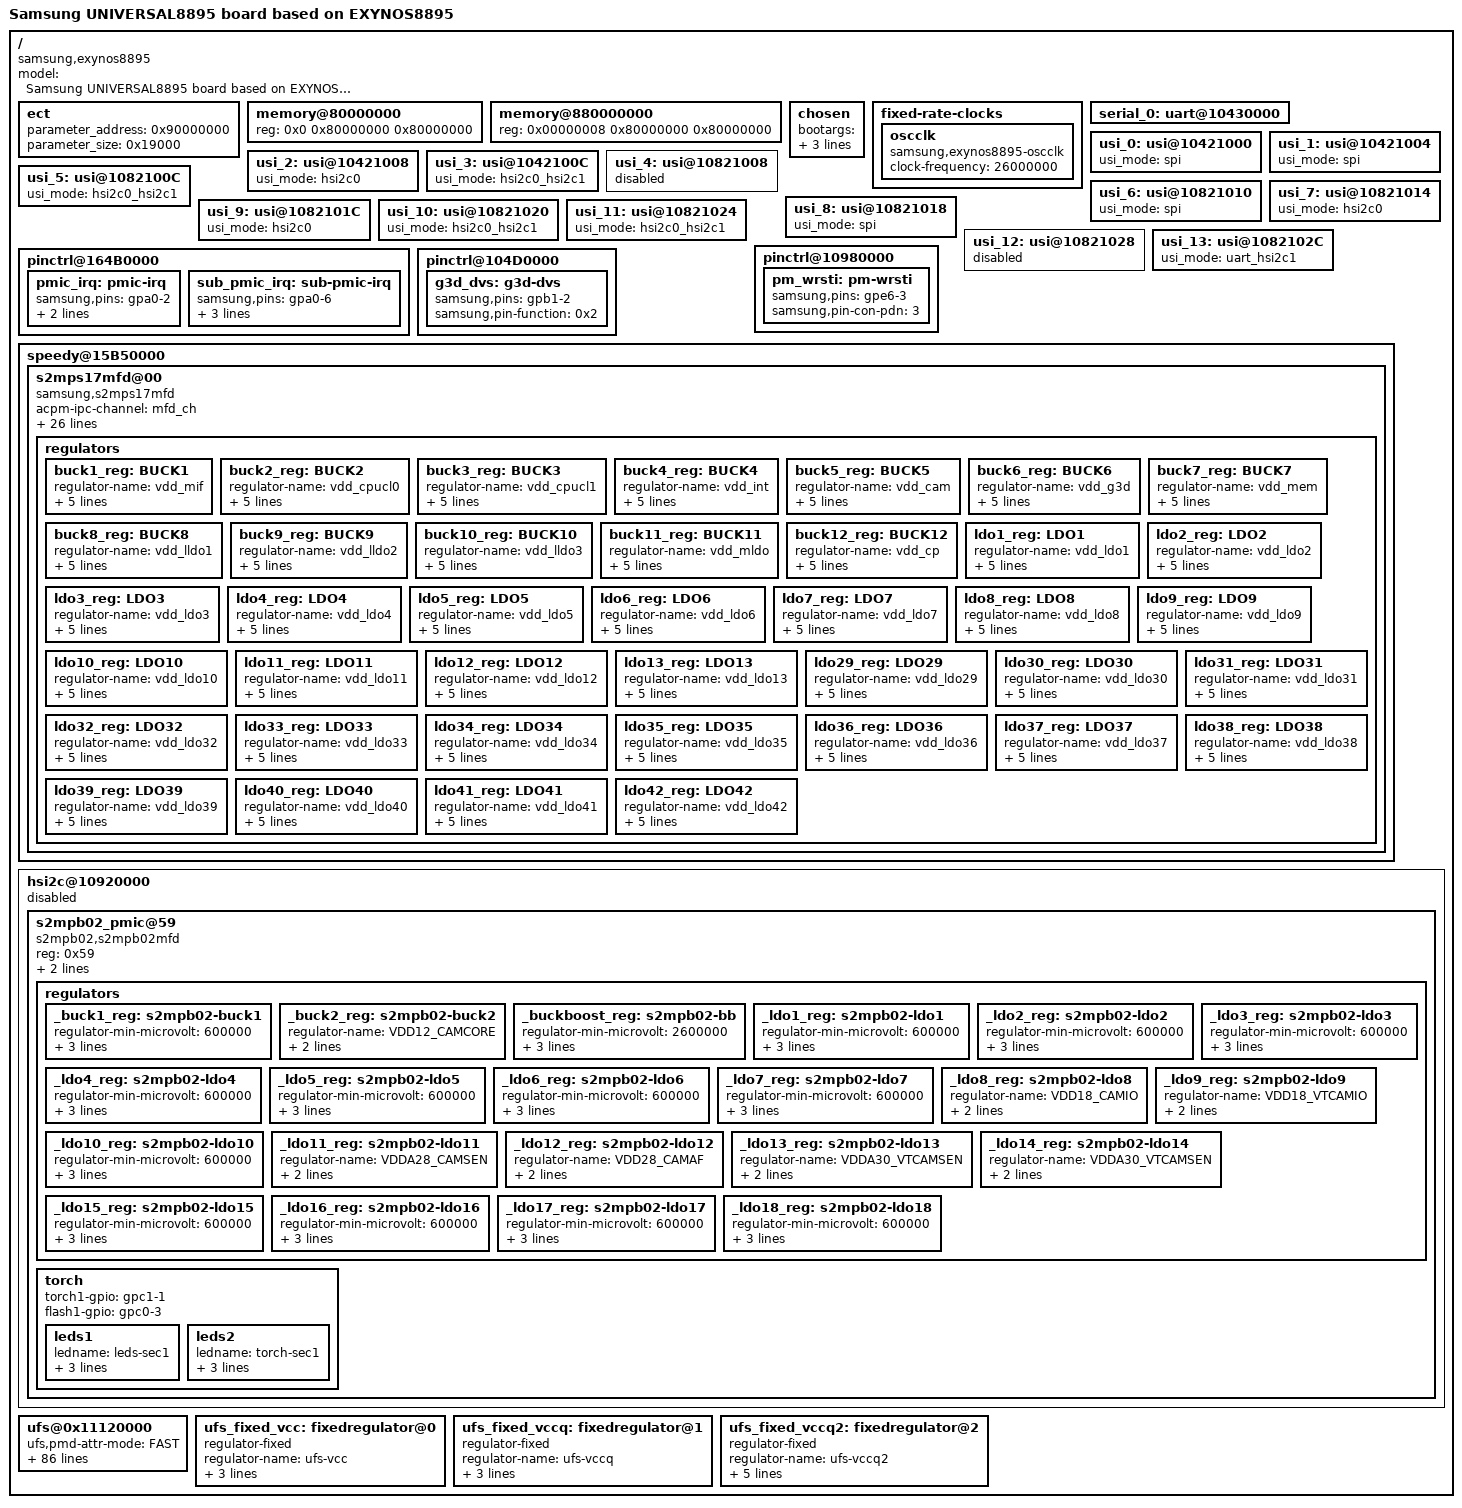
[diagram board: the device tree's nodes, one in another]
/*
 * SAMSUNG EXYNOS8895 board device tree source
 *
 * Copyright (c) 2016 Samsung Electronics Co., Ltd.
 *		http://www.samsung.com
 *
 * This program is free software; you can redistribute it and/or modify
 * it under the terms of the GNU General Public License version 2 as
 * published by the Free Software Foundation.
*/

/dts-v1/;
#include "exynos8895.dtsi"
#include "exynos8895-rmem.dtsi"

/ {
	model = "Samsung UNIVERSAL8895 board based on EXYNOS8895";
	compatible = "samsung,exynos8895", "samsung,UNIVERSAL8895";

	ect {
		parameter_address = <0x90000000>;
		parameter_size = <0x19000>;
	};

	memory@80000000 {
		device_type = "memory";
		reg = <0x0 0x80000000 0x80000000>;
	};

	memory@880000000 {
		device_type = "memory";
		reg = <0x00000008 0x80000000 0x80000000>;
	};

	chosen {
		bootargs = "earlycon=exynos,0x10430000,115200n8 console=ttySAC0,115200 root=/dev/ram0 rw ramdisk=8192 initrd=0x82000000,8M init=/linuxrc mem=768M clk_ignore_unused";
		linux,initrd-start = <0x82000000>;
		linux,initrd-end = <0x820FFFFF>;
	};

	fixed-rate-clocks {
		oscclk {
			compatible = "samsung,exynos8895-oscclk";
			clock-frequency = <26000000>;
		};
	};

	serial_0: uart@10430000 {
		status = "okay";
	};

	/* USI MODE SETTINGS

	   usi_mode = "hsi2c0" or "hsi2c1" or "spi" or "uart"
			or "hsi2c0_hsi2c1" or "uart_hsi2c1"
	 */
	usi_0: usi@10421000 {
		usi_mode = "spi";
		status = "okay";
	};

	usi_1: usi@10421004 {
		usi_mode = "spi";
		status = "okay";
	};

	usi_2: usi@10421008 {
		usi_mode = "hsi2c0";
		status = "okay";
	};

	usi_3: usi@1042100C {
		usi_mode = "hsi2c0_hsi2c1";
		status = "okay";
	};

	usi_4: usi@10821008 {
		status = "disabled";
	};

	usi_5: usi@1082100C {
		usi_mode = "hsi2c0_hsi2c1";
		status = "okay";
	};

	usi_6: usi@10821010 {
		usi_mode = "spi";
		status = "okay";
	};

	usi_7: usi@10821014 {
		usi_mode = "hsi2c0";
		status = "okay";
	};

	usi_8: usi@10821018 {
		usi_mode = "spi";
		status = "okay";
	};

	usi_9: usi@1082101C {
		usi_mode = "hsi2c0";
		status = "okay";
	};

	usi_10: usi@10821020 {
		usi_mode = "hsi2c0_hsi2c1";
		status = "okay";
	};

	usi_11: usi@10821024 {
		usi_mode = "hsi2c0_hsi2c1";
		status = "okay";
	};

	usi_12: usi@10821028 {
		status = "disabled";
	};

	usi_13: usi@1082102C {
		usi_mode = "uart_hsi2c1";
		status = "okay";
	};

	pinctrl@164B0000 {
		pmic_irq: pmic-irq {
			samsung,pins = "gpa0-2";
			samsung,pin-pud = <3>;
			samsung,pin-drv = <3>;
		};
		sub_pmic_irq: sub-pmic-irq {
			samsung,pins = "gpa0-6";
			samsung,pin-function = <0>;
			samsung,pin-pud = <0>;
			samsung,pin-drv = <0>;
		};
	};

	pinctrl@10980000 {
		/* Warm reset information from AP */
		pm_wrsti: pm-wrsti {
			samsung,pins = "gpe6-3";
			samsung,pin-con-pdn = <3>;
		};
	};

	pinctrl@104D0000 {
		g3d_dvs: g3d-dvs {
			samsung,pins = "gpb1-2";
			samsung,pin-function = <0x2>;
		};
	};

	speedy@15B50000{
		status = "okay";
		s2mps17mfd@00 {
			compatible = "samsung,s2mps17mfd";
			acpm-ipc-channel = <&mfd_ch>;
			i2c-speedy-address;
			s2mps17,wakeup = "enabled";
			s2mps17,irq-gpio = <&gpa0 2 0>;
			reg = <0x00>;
			interrupts = <2 0 0>;
			interrupt-parent = <&gpa0>;
			pinctrl-names = "default";
			pinctrl-0 = <&pmic_irq &pm_wrsti &g3d_dvs>;
			gpios = <&gpb1 3 0>, <&gpb1 2 0x2>;
			smpl_warn_en = <1>; /* 1 : enable , 0 : disable*/
			/* range of smpl_warn_vth */
			/* 0x00 : 2.1V, 0x20 : 2.3V, 0x40 : 2.5V, 0x60 : 2.7V 0x80 : 2.9V */
			/* 0xA0 : 3.1V, 0xC0 : 3.3V, 0xE0 : 3.5V */
			smpl_warn_vth = <0x80>;
			/* LowBat_Hys[4:3] 00(100mV), 01(200mV), 10(300mV), 11(400mV) */
			smpl_warn_hys = <0x00>;
			adc-on;
			cache_data = <1>; /* 1: enable, 0 : disable */
			g3d_en = <1>; /* 1 : enable , 0 : disable */
			/* RTC: wtsr/smpl */
			wtsr_en = <1>; /* enable */
			smpl_en = <1>; /* enable */
			wtsr_timer_val = <3>;	/* 1000ms */
			smpl_timer_val = <4>;	/* 500ms */
			check_jigon = <0>; /* do not check jigon */
			/* RTC: If it's first boot, reset rtc to 1/1/2014 12:00:00(Wed) */
			init_time,sec = <0>;
			init_time,min = <0>;
			init_time,hour = <12>;
			init_time,mday = <1>;
			init_time,mon = <0>;
			init_time,year = <116>;
			init_time,wday = <4>;

			regulators {
				buck1_reg: BUCK1 {
					regulator-name = "vdd_mif";
					regulator-min-microvolt = <450000>;
					regulator-max-microvolt = <950000>;
					regulator-always-on;
					regulator-ramp-delay = <12000>;
					regulator-initial-mode = <2>;
				};
				buck2_reg: BUCK2 {
					regulator-name = "vdd_cpucl0";
					regulator-min-microvolt = <450000>;
					regulator-max-microvolt = <1200000>;
					regulator-always-on;
					regulator-ramp-delay = <12000>;
					regulator-initial-mode = <2>;
				};

				buck3_reg: BUCK3 {
					regulator-name = "vdd_cpucl1";
					regulator-min-microvolt = <450000>;
					regulator-max-microvolt = <1200000>;
					regulator-always-on;
					regulator-ramp-delay = <12000>;
					regulator-initial-mode = <2>;
				};

				buck4_reg: BUCK4{
					regulator-name = "vdd_int";
					regulator-min-microvolt = <450000>;
					regulator-max-microvolt = <950000>;
					regulator-always-on;
					regulator-ramp-delay = <12000>;
					regulator-initial-mode = <2>;
				};

				buck5_reg: BUCK5 {
					regulator-name = "vdd_cam";
					regulator-min-microvolt = <450000>;
					regulator-max-microvolt = <950000>;
					regulator-always-on;
					regulator-ramp-delay = <12000>;
					regulator-initial-mode = <2>;
				};

				buck6_reg: BUCK6 {
					regulator-name = "vdd_g3d";
					regulator-min-microvolt = <450000>;
					regulator-max-microvolt = <850000>;
					regulator-always-on;
					regulator-ramp-delay = <12000>;
					regulator-initial-mode = <2>;
				};

				buck7_reg: BUCK7 {
					regulator-name = "vdd_mem";
					regulator-min-microvolt = <900000>;
					regulator-max-microvolt = <1300000>;
					regulator-always-on;
					regulator-ramp-delay = <12000>;
					regulator-initial-mode = <2>;
				};
				buck8_reg: BUCK8 {
					regulator-name = "vdd_lldo1";
					regulator-min-microvolt = <750000>;
					regulator-max-microvolt = <1150000>;
					regulator-always-on;
					regulator-ramp-delay = <12000>;
					regulator-initial-mode = <2>;
				};

				buck9_reg: BUCK9 {
					regulator-name = "vdd_lldo2";
					regulator-min-microvolt = <1100000>;
					regulator-max-microvolt = <1500000>;
					regulator-always-on;
					regulator-ramp-delay = <12000>;
					regulator-initial-mode = <2>;
				};

				buck10_reg: BUCK10 {
					regulator-name = "vdd_lldo3";
					regulator-min-microvolt = <1100000>;
					regulator-max-microvolt = <1500000>;
					regulator-always-on;
					regulator-ramp-delay = <12000>;
					regulator-initial-mode = <2>;
				};

				buck11_reg: BUCK11 {
					regulator-name = "vdd_mldo";
					regulator-min-microvolt = <1750000>;
					regulator-max-microvolt = <2150000>;
					regulator-always-on;
					regulator-ramp-delay = <12000>;
					regulator-initial-mode = <2>;
				};

				buck12_reg: BUCK12 {
					regulator-name = "vdd_cp";
					regulator-min-microvolt = <450000>;
					regulator-max-microvolt = <950000>;
					regulator-always-on;
					regulator-ramp-delay = <12000>;
					regulator-initial-mode = <2>;
				};

				ldo1_reg: LDO1 {
					regulator-name = "vdd_ldo1";
					regulator-min-microvolt = <700000>;
					regulator-max-microvolt = <950000>;
					regulator-always-on;
					regulator-ramp-delay = <12000>;
					regulator-initial-mode = <2>;
				};

				ldo2_reg: LDO2 {
					regulator-name = "vdd_ldo2";
					regulator-min-microvolt = <1700000>;
					regulator-max-microvolt = <3300000>;
					regulator-always-on;
					regulator-ramp-delay = <12000>;
					regulator-initial-mode = <2>;
				};

				ldo3_reg: LDO3 {
					regulator-name = "vdd_ldo3";
					regulator-min-microvolt = <1620000>;
					regulator-max-microvolt = <1980000>;
					regulator-always-on;
					regulator-ramp-delay = <12000>;
					regulator-initial-mode = <3>;
				};

				ldo4_reg: LDO4 {
					regulator-name = "vdd_ldo4";
					regulator-min-microvolt = <700000>;
					regulator-max-microvolt = <950000>;
					regulator-always-on;
					regulator-ramp-delay = <12000>;
					regulator-initial-mode = <2>;
				};

				ldo5_reg: LDO5 {
					regulator-name = "vdd_ldo5";
					regulator-min-microvolt = <1620000>;
					regulator-max-microvolt = <1980000>;
					regulator-always-on;
					regulator-ramp-delay = <12000>;
					regulator-initial-mode = <2>;
				};

				ldo6_reg: LDO6 {
					regulator-name = "vdd_ldo6";
					regulator-min-microvolt = <1700000>;
					regulator-max-microvolt = <3350000>;
					regulator-always-on;
					regulator-ramp-delay = <12000>;
					regulator-initial-mode = <2>;
				};

				ldo7_reg: LDO7 {
					regulator-name = "vdd_ldo7";
					regulator-min-microvolt = <450000>;
					regulator-max-microvolt = <1200000>;
					regulator-always-on;
					regulator-ramp-delay = <12000>;
					regulator-initial-mode = <2>;
				};

				ldo8_reg: LDO8 {
					regulator-name = "vdd_ldo8";
					regulator-min-microvolt = <450000>;
					regulator-max-microvolt = <950000>;
					regulator-always-on;
					regulator-ramp-delay = <12000>;
					regulator-initial-mode = <2>;
				};

				ldo9_reg: LDO9 {
					regulator-name = "vdd_ldo9";
					regulator-min-microvolt = <450000>;
					regulator-max-microvolt = <950000>;
					regulator-always-on;
					regulator-ramp-delay = <12000>;
					regulator-initial-mode = <2>;
				};

				ldo10_reg: LDO10 {
					regulator-name = "vdd_ldo10";
					regulator-min-microvolt = <700000>;
					regulator-max-microvolt = <950000>;
					regulator-always-on;
					regulator-ramp-delay = <12000>;
					regulator-initial-mode = <2>;
				};


				ldo11_reg: LDO11 {
					regulator-name = "vdd_ldo11";
					regulator-min-microvolt = <450000>;
					regulator-max-microvolt = <950000>;
					regulator-always-on;
					regulator-ramp-delay = <12000>;
					regulator-initial-mode = <2>;
				};

				ldo12_reg: LDO12 {
					regulator-name = "vdd_ldo12";
					regulator-min-microvolt = <450000>;
					regulator-max-microvolt = <950000>;
					regulator-always-on;
					regulator-ramp-delay = <12000>;
					regulator-initial-mode = <2>;
				};

				ldo13_reg: LDO13 {
					regulator-name = "vdd_ldo13";
					regulator-min-microvolt = <900000>;
					regulator-max-microvolt = <1300000>;
					regulator-always-on;
					regulator-ramp-delay = <12000>;
					regulator-initial-mode = <2>;
				};

				ldo29_reg: LDO29 {
					regulator-name = "vdd_ldo29";
					regulator-min-microvolt = <1800000>;
					regulator-max-microvolt = <3375000>;
					regulator-always-on;
					regulator-ramp-delay = <12000>;
					regulator-initial-mode = <2>;
				};

				ldo30_reg: LDO30 {
					regulator-name = "vdd_ldo30";
					regulator-min-microvolt = <1800000>;
					regulator-max-microvolt = <3375000>;
					regulator-always-on;
					regulator-ramp-delay = <12000>;
					regulator-initial-mode = <2>;
				};
				ldo31_reg: LDO31 {
					regulator-name = "vdd_ldo31";
					regulator-min-microvolt = <1800000>;
					regulator-max-microvolt = <3375000>;
					regulator-always-on;
					regulator-ramp-delay = <12000>;
					regulator-initial-mode = <2>;
				};
				ldo32_reg: LDO32 {
					regulator-name = "vdd_ldo32";
					regulator-min-microvolt = <700000>;
					regulator-max-microvolt = <2275000>;
					regulator-always-on;
					regulator-ramp-delay = <12000>;
					regulator-initial-mode = <2>;
				};
				ldo33_reg: LDO33 {
					regulator-name = "vdd_ldo33";
					regulator-min-microvolt = <700000>;
					regulator-max-microvolt = <1487500>;
					regulator-always-on;
					regulator-ramp-delay = <12000>;
					regulator-initial-mode = <2>;
				};
				ldo34_reg: LDO34 {
					regulator-name = "vdd_ldo34";
					regulator-min-microvolt = <700000>;
					regulator-max-microvolt = <2275000>;
					regulator-always-on;
					regulator-ramp-delay = <12000>;
					regulator-initial-mode = <2>;
				};
				ldo35_reg: LDO35 {
					regulator-name = "vdd_ldo35";
					regulator-min-microvolt = <1800000>;
					regulator-max-microvolt = <3375000>;
					regulator-always-on;
					regulator-ramp-delay = <12000>;
					regulator-initial-mode = <2>;
				};
				ldo36_reg: LDO36 {
					regulator-name = "vdd_ldo36";
					regulator-min-microvolt = <1800000>;
					regulator-max-microvolt = <3375000>;
					regulator-always-on;
					regulator-ramp-delay = <12000>;
					regulator-initial-mode = <2>;
				};
				ldo37_reg: LDO37 {
					regulator-name = "vdd_ldo37";
					regulator-min-microvolt = <1800000>;
					regulator-max-microvolt = <3375000>;
					regulator-always-on;
					regulator-ramp-delay = <12000>;
					regulator-initial-mode = <2>;
				};
				ldo38_reg: LDO38 {
					regulator-name = "vdd_ldo38";
					regulator-min-microvolt = <700000>;
					regulator-max-microvolt = <2275000>;
					regulator-always-on;
					regulator-ramp-delay = <12000>;
					regulator-initial-mode = <2>;
				};
				ldo39_reg: LDO39 {
					regulator-name = "vdd_ldo39";
					regulator-min-microvolt = <700000>;
					regulator-max-microvolt = <2275000>;
					regulator-always-on;
					regulator-ramp-delay = <12000>;
					regulator-initial-mode = <2>;
				};
				ldo40_reg: LDO40 {
					regulator-name = "vdd_ldo40";
					regulator-min-microvolt = <700000>;
					regulator-max-microvolt = <1487500>;
					regulator-always-on;
					regulator-ramp-delay = <12000>;
					regulator-initial-mode = <2>;
				};
				ldo41_reg: LDO41 {
					regulator-name = "vdd_ldo41";
					regulator-min-microvolt = <1800000>;
					regulator-max-microvolt = <3375000>;
					regulator-always-on;
					regulator-ramp-delay = <12000>;
					regulator-initial-mode = <2>;
				};
				ldo42_reg: LDO42 {
					regulator-name = "vdd_ldo42";
					regulator-min-microvolt = <700000>;
					regulator-max-microvolt = <2275000>;
					regulator-always-on;
					regulator-ramp-delay = <12000>;
					regulator-initial-mode = <2>;
				};
			};
		};
	};

	hsi2c@10920000 {
		status = "disabled";
		s2mpb02_pmic@59 {
			compatible = "s2mpb02,s2mpb02mfd";
			reg = <0x59>;

			s2mpb02,wakeup;
			pinctrl-names = "default";
			pinctrl-0 = <&sub_pmic_irq>;

			regulators {
				_buck1_reg: s2mpb02-buck1 {
					regulator-min-microvolt = <600000>;
					regulator-max-microvolt = <1700000>;
					regulator-always-on;
					regulator-boot-on;
				};

				_buck2_reg: s2mpb02-buck2 {
					regulator-name = "VDD12_CAMCORE";
					regulator-min-microvolt = <600000>;
					regulator-max-microvolt = <1500000>;
				};

				_buckboost_reg: s2mpb02-bb {
					regulator-min-microvolt = <2600000>;
					regulator-max-microvolt = <4000000>;
					regulator-always-on;
					regulator-boot-on;
				};

				_ldo1_reg: s2mpb02-ldo1 {
					regulator-min-microvolt = <600000>;
					regulator-max-microvolt = <2187500>;
					regulator-always-on;
					regulator-boot-on;
				};

				_ldo2_reg: s2mpb02-ldo2 {
					regulator-min-microvolt = <600000>;
					regulator-max-microvolt = <2187500>;
					regulator-always-on;
					regulator-boot-on;
				};

				_ldo3_reg: s2mpb02-ldo3 {
					regulator-min-microvolt = <600000>;
					regulator-max-microvolt = <2187500>;
					regulator-always-on;
					regulator-boot-on;
				};

				_ldo4_reg: s2mpb02-ldo4 {
					regulator-min-microvolt = <600000>;
					regulator-max-microvolt = <2187500>;
					regulator-always-on;
					regulator-boot-on;
				};

				_ldo5_reg: s2mpb02-ldo5 {
					regulator-min-microvolt = <600000>;
					regulator-max-microvolt = <2187500>;
					regulator-always-on;
					regulator-boot-on;
				};

				_ldo6_reg: s2mpb02-ldo6 {
					regulator-min-microvolt = <600000>;
					regulator-max-microvolt = <3775000>;
					regulator-always-on;
					regulator-boot-on;
				};

				_ldo7_reg: s2mpb02-ldo7 {
					regulator-min-microvolt = <600000>;
					regulator-max-microvolt = <3775000>;
					regulator-always-on;
					regulator-boot-on;
				};

				_ldo8_reg: s2mpb02-ldo8 {
					regulator-name = "VDD18_CAMIO";
					regulator-min-microvolt = <1800000>;
					regulator-max-microvolt = <1800000>;
				};

				_ldo9_reg: s2mpb02-ldo9 {
					regulator-name = "VDD18_VTCAMIO";
					regulator-min-microvolt = <1800000>;
					regulator-max-microvolt = <1800000>;
				};

				_ldo10_reg: s2mpb02-ldo10 {
					regulator-min-microvolt = <600000>;
					regulator-max-microvolt = <3775000>;
					regulator-always-on;
					regulator-boot-on;
				};

				_ldo11_reg: s2mpb02-ldo11 {
					regulator-name = "VDDA28_CAMSEN";
					regulator-min-microvolt = <2800000>;
					regulator-max-microvolt = <2800000>;
				};

				_ldo12_reg: s2mpb02-ldo12 {
					regulator-name = "VDD28_CAMAF";
					regulator-min-microvolt = <1800000>;
					regulator-max-microvolt = <3375000>;
				};

				_ldo13_reg: s2mpb02-ldo13 {
					regulator-name = "VDDA30_VTCAMSEN";
					regulator-min-microvolt = <2800000>;
					regulator-max-microvolt = <3775000>;
				};

				_ldo14_reg: s2mpb02-ldo14 {
					regulator-name = "VDDA30_VTCAMSEN";
					regulator-min-microvolt = <2800000>;
					regulator-max-microvolt = <2800000>;
				};

				_ldo15_reg: s2mpb02-ldo15 {
					regulator-min-microvolt = <600000>;
					regulator-max-microvolt = <3775000>;
					regulator-always-on;
					regulator-boot-on;
				};

				_ldo16_reg: s2mpb02-ldo16 {
					regulator-min-microvolt = <600000>;
					regulator-max-microvolt = <3775000>;
					regulator-always-on;
					regulator-boot-on;
				};

				_ldo17_reg: s2mpb02-ldo17 {
					regulator-min-microvolt = <600000>;
					regulator-max-microvolt = <3775000>;
					regulator-always-on;
					regulator-boot-on;
				};

				_ldo18_reg: s2mpb02-ldo18 {
					regulator-min-microvolt = <600000>;
					regulator-max-microvolt = <3775000>;
					regulator-always-on;
					regulator-boot-on;
				};
			};

			torch {
				torch1-gpio = "gpc1-1";
				flash1-gpio = "gpc0-3";

				status = "okay";

				leds1 {
					ledname = "leds-sec1";
					id = <0>;
					brightness = <0xC>;
					timeout = <0x3>;
				};

				leds2 {
					ledname = "torch-sec1";
					id = <1>;
					brightness = <0xC>;
					timeout = <0xF>;
				};
			};
		};
	};

	ufs@0x11120000 {
		status = "okay";
		ufs,pmd-attr-mode = "FAST";
		ufs,pmd-attr-lane = /bits/ 8 <2>;
		ufs,pmd-attr-gear = /bits/ 8 <3>;
		ufs,pmd-attr-hs-series = "HS_rate_b";
		ufs-opts-skip-connection-estab;
		ufs-opts-use-seperated-pclk;
		ufs-rx-adv-fine-gran-sup_en = <0>;
		ufs-rx-min-activate-time-cap = <3>;
		ufs-rx-hibern8-time-cap = <2>;
		ufs-tx-hibern8-time-cap = <2>;
		//ufs-wait-cdr-lock = <0x6e>;
		//KC
		ufs-wait-cdr-lock = <0x1fc>;

		vcc-supply = <&ufs_fixed_vcc>;
		vccq-supply = <&ufs_fixed_vccq>;
		vccq2-supply = <&ufs_fixed_vccq2>;
		vcc-fixed-regulator;
		vccq-fixed-regulator;
		vccq2-fixed-regulator;

		ufs-cap-clk-gating;
		ufs-cap-hibern8-with-clk-gating;

		phy-init =
			<0x9514 0x00 PMD_ALL UNIPRO_DBG_PRD>,		//Unipro Clock Period
			<0x200 0x40 PMD_ALL PHY_PCS_COMN>,			//OV_TM On
			<0x12 0x00 PMD_ALL PHY_PCS_RX_PRD>,			//PCS RX Clock Period
			<0xAA 0x00 PMD_ALL PHY_PCS_TX_PRD>,			//PCS TX Clock Period
			<0x5C 0x38 PMD_ALL PHY_PCS_RX>,
			<0x0F 0x0 PMD_ALL PHY_PCS_RX>,
			<0x65 0x01 PMD_ALL PHY_PCS_RX>,				//PCS RX INT_H8_COUNT_CAP_ENABLE[0] = 1b'1(THIBERN8 CAPABILITY(200us))
			<0x200 0x0 PMD_ALL PHY_PCS_COMN>,			//OV_TM Off
			<0x9564 0x2e820183 PMD_ALL UNIPRO_DBG_MIB>,	//DBG_PA_OPTION_SUITE
			<0x155E 0x0 PMD_ALL UNIPRO_STD_MIB>,			//LCC disable

			<0x3000 0x0 PMD_ALL UNIPRO_STD_MIB>,			//N_DeviceID
			<0x3001 0x1 PMD_ALL UNIPRO_STD_MIB>,			//N_DeviceID_valid
			<0x4021 0x1 PMD_ALL UNIPRO_STD_MIB>,			//T_PeerDeviceID

			<0x4020 0x1 PMD_ALL UNIPRO_STD_MIB>,			//T_ConnectionState

			<0x74 0x10 PMD_ALL PHY_PMA_COMN>,			//CMN_1D(0x74),	PWM clock generation selection: CMN_REG1D(0x10 = Refclk, 0x20 = int OSC)
			<0x110 0xB5 PMD_ALL PHY_PMA_TRSV>,			//TRSVx_14(0x110/0x250), TRSVx_REG14(RXAFE_DIFN_SQ_PULSE_REJ_EN = 1b'0)
			<0x134 0x43 PMD_ALL PHY_PMA_TRSV>,			//TRSVx_1D(0x134/0x274),
			<0x16C 0x20 PMD_ALL PHY_PMA_TRSV>,			//TRSVx_2B(0x16C/0x2AC),
			<0x178 0xC0 PMD_ALL PHY_PMA_TRSV>,			//TRSVx_2E(0x178/0x2B8),
			<0 0 0 0>;

		post-phy-init =
			<0x9529 0x1 PMD_ALL UNIPRO_DBG_MIB>,			//Unipro Debug Mode On
			<0x15A4 0xFA PMD_ALL UNIPRO_STD_MIB>,		//PA_SaveConfigTime
			<0x9529 0x0 PMD_ALL UNIPRO_DBG_MIB>,			//Unipro Debug Mode Off
			<0 0 0 0>;

		calib-of-pwm =
			<0x1569 0x0 PMD_PWM UNIPRO_STD_MIB>,
			<0x1584 0x0 PMD_PWM UNIPRO_STD_MIB>,
			<0x2041 8064 PMD_PWM UNIPRO_STD_MIB>,
			<0x2042 28224 PMD_PWM UNIPRO_STD_MIB>,
			<0x2043 20160 PMD_PWM UNIPRO_STD_MIB>,
			<0x15B0 12000 PMD_PWM UNIPRO_STD_MIB>,
			<0x15B1 32000 PMD_PWM UNIPRO_STD_MIB>,
			<0x15B2 16000 PMD_PWM UNIPRO_STD_MIB>,
			<0x7888 8064 PMD_PWM UNIPRO_DBG_APB>,
			<0x788C 28224 PMD_PWM UNIPRO_DBG_APB>,
			<0x7890 20160 PMD_PWM UNIPRO_DBG_APB>,
			<0x78B8 12000 PMD_PWM UNIPRO_DBG_APB>,
			<0x78BC 32000 PMD_PWM UNIPRO_DBG_APB>,
			<0x78C0 16000 PMD_PWM UNIPRO_DBG_APB>,
			<0 0 0 0>;

		calib-of-hs-rate-a =
			<0x1569 0x1 PMD_HS UNIPRO_STD_MIB>,
			<0x1584 0x1 PMD_HS UNIPRO_STD_MIB>,

			<0x2041 8064 PMD_HS UNIPRO_STD_MIB>,
			<0x2042 28224 PMD_HS UNIPRO_STD_MIB>,
			<0x2043 20160 PMD_HS UNIPRO_STD_MIB>,
			<0x15B0 12000 PMD_HS UNIPRO_STD_MIB>,
			<0x15B1 32000 PMD_HS UNIPRO_STD_MIB>,
			<0x15B2 16000 PMD_HS UNIPRO_STD_MIB>,

			<0x7888 8064 PMD_HS UNIPRO_DBG_APB>,
			<0x788C 28224 PMD_HS UNIPRO_DBG_APB>,
			<0x7890 20160 PMD_HS UNIPRO_DBG_APB>,
			<0x78B8 12000 PMD_HS UNIPRO_DBG_APB>,
			<0x78BC 32000 PMD_HS UNIPRO_DBG_APB>,
			<0x78C0 16000 PMD_HS UNIPRO_DBG_APB>,
			<0 0 0 0>;

		calib-of-hs-rate-b =
			<0x1569 0x1 PMD_HS UNIPRO_STD_MIB>,
			<0x1584 0x1 PMD_HS UNIPRO_STD_MIB>,

			<0x2041 8064 PMD_HS UNIPRO_STD_MIB>,
			<0x2042 28224 PMD_HS UNIPRO_STD_MIB>,
			<0x2043 20160 PMD_HS UNIPRO_STD_MIB>,
			<0x15B0 12000 PMD_HS UNIPRO_STD_MIB>,
			<0x15B1 32000 PMD_HS UNIPRO_STD_MIB>,
			<0x15B2 16000 PMD_HS UNIPRO_STD_MIB>,

			<0x7888 8064 PMD_HS UNIPRO_DBG_APB>,
			<0x788C 28224 PMD_HS UNIPRO_DBG_APB>,
			<0x7890 20160 PMD_HS UNIPRO_DBG_APB>,
			<0x78B8 12000 PMD_HS UNIPRO_DBG_APB>,
			<0x78BC 32000 PMD_HS UNIPRO_DBG_APB>,
			<0x78C0 16000 PMD_HS UNIPRO_DBG_APB>,
			<0 0 0 0>;

//		post-calib-of-pwm =
//			<0 0 0 0>;

//		post-calib-of-hs-rate-a =
//			<0 0 0 0>;

//		post-calib-of-hs-rate-b =
//			<0 0 0 0>;

//		pma-restore =
//			<0 0 0 0>;
	};

	ufs_fixed_vcc: fixedregulator@0 {
		       compatible = "regulator-fixed";
		       regulator-name = "ufs-vcc";
		       gpio = <&gpg0 0 0>;
		       regulator-boot-on;
		       enable-active-high;
	};

	ufs_fixed_vccq: fixedregulator@1 {
			compatible = "regulator-fixed";
			regulator-name = "ufs-vccq";
			gpio = <&gpg0 0 0>;
			regulator-boot-on;
			enable-active-high;
	};

	ufs_fixed_vccq2: fixedregulator@2 {
			 compatible = "regulator-fixed";
			 regulator-name = "ufs-vccq2";
			 gpio = <&gpg0 0 0>;
			 regulator-boot-on;
			 enable-active-high;
			 startup-delay-us = <2000>;
			 endup-delay-us = <2000>;
	};
};
